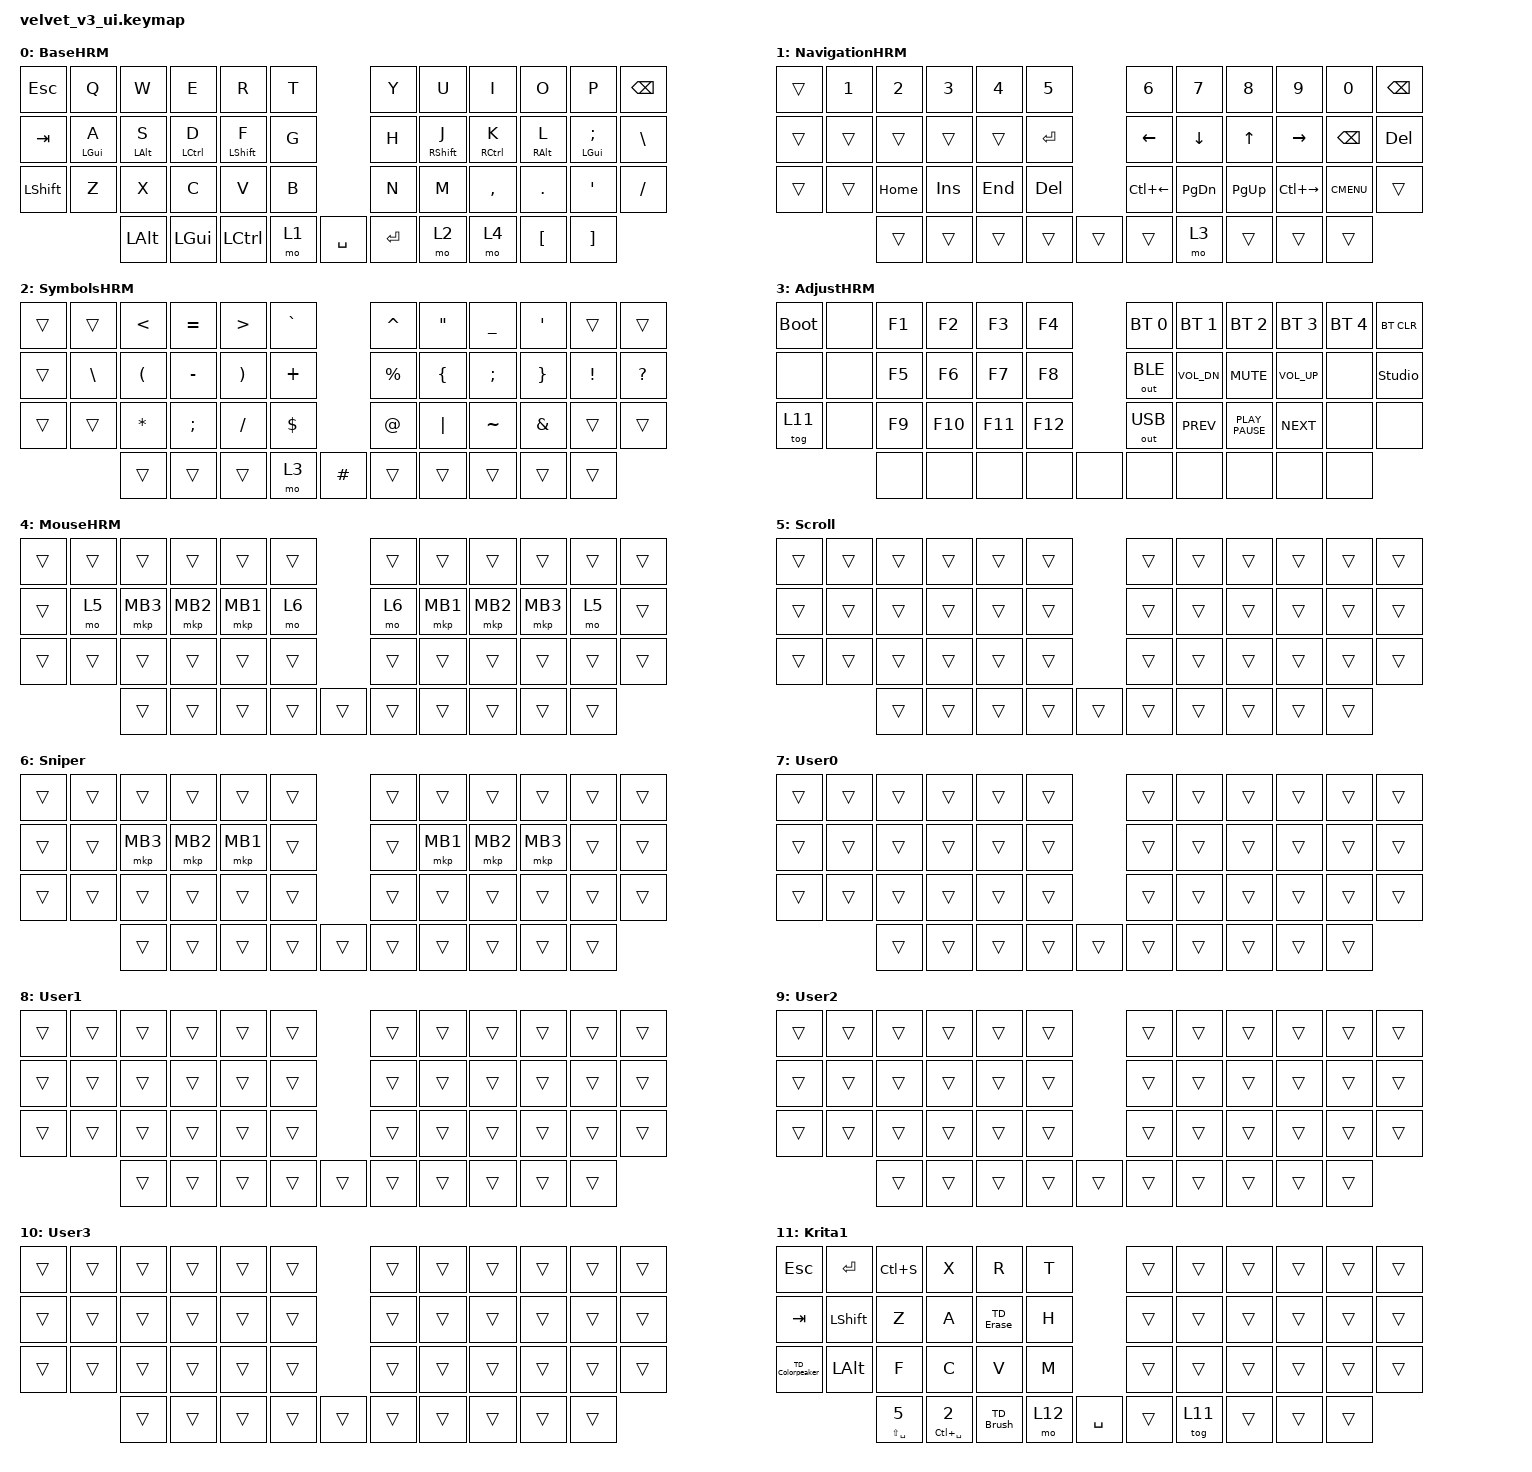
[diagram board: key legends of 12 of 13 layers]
#include <dt-bindings/zmk/input_transform.h>
#include <input/processors.dtsi>
#include <zephyr/dt-bindings/input/input-event-codes.h>
#include <behaviors.dtsi>
#include <dt-bindings/zmk/bt.h>
#include <dt-bindings/zmk/keys.h>
#include <dt-bindings/zmk/outputs.h>
#include <dt-bindings/zmk/pointing.h>

/ {
    behaviors {
        cap_sen: cap_sen {
            compatible = "zmk,behavior-hold-tap";
            label = "CAP_SEN";
            bindings = <&mo>, <&mkp>;

            #binding-cells = <2>;
            tapping-term-ms = <150>;
        };

        hrml: hrml {
            compatible = "zmk,behavior-hold-tap";
            label = "HRML";
            bindings = <&kp>, <&kp>;

            #binding-cells = <2>;
            tapping-term-ms = <200>;
            quick-tap-ms = <175>;
            require-prior-idle-ms = <150>;
            flavor = "balanced";
            hold-trigger-on-release;
            hold-trigger-key-positions = <6 7 8 9 10 11 18 19 20 21 22 23 30 31 32 33 34 35 42 43 44 45 41>;
        };

        hrmr: hrmr {
            compatible = "zmk,behavior-hold-tap";
            label = "HRMR";
            bindings = <&kp>, <&kp>;

            #binding-cells = <2>;
            tapping-term-ms = <200>;
            quick-tap-ms = <175>;
            require-prior-idle-ms = <150>;
            flavor = "balanced";
            hold-trigger-on-release;
            hold-trigger-key-positions = <0 1 2 3 4 5 12 13 14 15 16 17 24 25 26 27 28 29 36 37 38 39 40>;
        };

        TD_Brush: TD_Brush {
            compatible = "zmk,behavior-tap-dance";
            label = "TD_BRUSH";
            #binding-cells = <0>;
            bindings = <&kp B>, <&kp Q>;
        };

        TD_Erase: TD_Erase {
            compatible = "zmk,behavior-tap-dance";
            label = "TD_ERASE";
            #binding-cells = <0>;
            bindings = <&kp E>, <&kp LA(E)>;
        };

        TD_Colorpeaker: TD_Colorpeaker {
            compatible = "zmk,behavior-tap-dance";
            label = "TD_COLORPEAKER";
            #binding-cells = <0>;
            bindings = <&kp LCTRL>, <&kp LA(LCTRL)>;
        };
    };

    combos {
        compatible = "zmk,combos";

        tilde {
            bindings = <&kp GRAVE>;
            key-positions = <3 4>;
            layers = <0>;
        };
    };

    keymap {
        compatible = "zmk,keymap";

        BaseHRM {
            label = "BaseHRM";
            bindings = <
&kp ESC    &kp Q             &kp W             &kp E          &kp R               &kp T                        &kp Y  &kp U          &kp I          &kp O         &kp P                 &kp BSPC
&kp TAB    &hrml LEFT_GUI A  &hrml LEFT_ALT S  &hrml LCTRL D  &hrml LEFT_SHIFT F  &kp G                        &kp H  &hrmr RSHFT J  &hrmr RCTRL K  &hrmr RALT L  &hrmr LGUI SEMICOLON  &kp BSLH
&kp LSHFT  &kp Z             &kp X             &kp C          &kp V               &kp B                        &kp N  &kp M          &kp COMMA      &kp DOT       &kp SQT               &kp SLASH
                             &kp LALT          &kp LGUI       &kp LCTRL           &mo 1  &kp SPACE    &kp RET  &mo 2  &mo 4          &kp LBKT       &kp RBKT
            >;
        };

        NavigationHRM {
            label = "NavigationHRM";
            bindings = <
&trans  &kp N1  &kp N2    &kp N3   &kp N4   &kp N5                     &kp N6          &kp N7          &kp N8        &kp N9         &kp N0         &kp BACKSPACE
&trans  &trans  &trans    &trans   &trans   &kp RET                    &kp LEFT_ARROW  &kp DOWN_ARROW  &kp UP_ARROW  &kp RIGHT      &kp BACKSPACE  &kp DELETE
&trans  &trans  &kp HOME  &kp INS  &kp END  &kp DEL                    &kp LC(LEFT)    &kp PAGE_DOWN   &kp PAGE_UP   &kp LC(RIGHT)  &kp K_CMENU    &trans
                &trans    &trans   &trans   &trans   &trans    &trans  &mo 3           &trans          &trans        &trans
            >;
        };

        SymbolsHRM {
            label = "SymbolsHRM";
            bindings = <
&trans  &trans    &kp LT    &kp EQUAL  &kp GT    &kp GRAVE                      &kp CARET  &kp DQT   &kp UNDER  &kp SQT   &trans    &trans
&trans  &kp BSLH  &kp LPAR  &kp MINUS  &kp RPAR  &kp PLUS                       &kp PRCNT  &kp LBRC  &kp SEMI   &kp RBRC  &kp EXCL  &kp QUESTION
&trans  &trans    &kp STAR  &kp SEMI   &kp FSLH  &kp DLLR                       &kp AT     &kp PIPE  &kp TILDE  &kp AMPS  &trans    &trans
                  &trans    &trans     &trans    &mo 3      &kp HASH    &trans  &trans     &trans    &trans     &trans
            >;
        };

        AdjustHRM {
            label = "AdjustHRM";
            bindings = <
&bootloader  &none  &kp F1  &kp F2   &kp F3   &kp F4                   &bt BT_SEL 0  &bt BT_SEL 1  &bt BT_SEL 2      &bt BT_SEL 3  &bt BT_SEL 4  &bt BT_CLR
&none        &none  &kp F5  &kp F6   &kp F7   &kp F8                   &out OUT_BLE  &kp C_VOL_DN  &kp K_MUTE        &kp C_VOL_UP  &none         &studio_unlock
&tog 11      &none  &kp F9  &kp F10  &kp F11  &kp F12                  &out OUT_USB  &kp K_PREV    &kp K_PLAY_PAUSE  &kp K_NEXT    &none         &none
                    &none   &none    &none    &none    &none    &none  &none         &none         &none             &none
            >;
        };

        MouseHRM {
            bindings = <
&trans  &trans  &trans    &trans    &trans    &trans                    &trans  &trans    &trans    &trans    &trans  &trans
&trans  &mo 5   &mkp MB3  &mkp MB2  &mkp MB1  &mo 6                     &mo 6   &mkp MB1  &mkp MB2  &mkp MB3  &mo 5   &trans
&trans  &trans  &trans    &trans    &trans    &trans                    &trans  &trans    &trans    &trans    &trans  &trans
                &trans    &trans    &trans    &trans  &trans    &trans  &trans  &trans    &trans    &trans
            >;
        };

        Scroll {
            bindings = <
&trans  &trans  &trans  &trans  &trans  &trans                    &trans  &trans  &trans  &trans  &trans  &trans
&trans  &trans  &trans  &trans  &trans  &trans                    &trans  &trans  &trans  &trans  &trans  &trans
&trans  &trans  &trans  &trans  &trans  &trans                    &trans  &trans  &trans  &trans  &trans  &trans
                &trans  &trans  &trans  &trans  &trans    &trans  &trans  &trans  &trans  &trans
            >;
        };

        Sniper {
            bindings = <
&trans  &trans  &trans    &trans    &trans    &trans                    &trans  &trans    &trans    &trans    &trans  &trans
&trans  &trans  &mkp MB3  &mkp MB2  &mkp MB1  &trans                    &trans  &mkp MB1  &mkp MB2  &mkp MB3  &trans  &trans
&trans  &trans  &trans    &trans    &trans    &trans                    &trans  &trans    &trans    &trans    &trans  &trans
                &trans    &trans    &trans    &trans  &trans    &trans  &trans  &trans    &trans    &trans
            >;
        };

        User0 {
            bindings = <
&trans  &trans  &trans  &trans  &trans  &trans                    &trans  &trans  &trans  &trans  &trans  &trans
&trans  &trans  &trans  &trans  &trans  &trans                    &trans  &trans  &trans  &trans  &trans  &trans
&trans  &trans  &trans  &trans  &trans  &trans                    &trans  &trans  &trans  &trans  &trans  &trans
                &trans  &trans  &trans  &trans  &trans    &trans  &trans  &trans  &trans  &trans
            >;

            label = "User0";
        };

        User1 {
            bindings = <
&trans  &trans  &trans  &trans  &trans  &trans                    &trans  &trans  &trans  &trans  &trans  &trans
&trans  &trans  &trans  &trans  &trans  &trans                    &trans  &trans  &trans  &trans  &trans  &trans
&trans  &trans  &trans  &trans  &trans  &trans                    &trans  &trans  &trans  &trans  &trans  &trans
                &trans  &trans  &trans  &trans  &trans    &trans  &trans  &trans  &trans  &trans
            >;

            label = "User1";
        };

        User2 {
            bindings = <
&trans  &trans  &trans  &trans  &trans  &trans                    &trans  &trans  &trans  &trans  &trans  &trans
&trans  &trans  &trans  &trans  &trans  &trans                    &trans  &trans  &trans  &trans  &trans  &trans
&trans  &trans  &trans  &trans  &trans  &trans                    &trans  &trans  &trans  &trans  &trans  &trans
                &trans  &trans  &trans  &trans  &trans    &trans  &trans  &trans  &trans  &trans
            >;

            label = "User2";
        };

        User3 {
            bindings = <
&trans  &trans  &trans  &trans  &trans  &trans                    &trans  &trans  &trans  &trans  &trans  &trans
&trans  &trans  &trans  &trans  &trans  &trans                    &trans  &trans  &trans  &trans  &trans  &trans
&trans  &trans  &trans  &trans  &trans  &trans                    &trans  &trans  &trans  &trans  &trans  &trans
                &trans  &trans  &trans  &trans  &trans    &trans  &trans  &trans  &trans  &trans
            >;

            label = "User3";
        };

        Krita1 {
            bindings = <
&kp ESC          &kp RET    &kp LC(S)         &kp X                   &kp R      &kp T                        &trans   &trans  &trans  &trans  &trans  &trans
&kp TAB          &kp LSHFT  &kp Z             &kp A                   &TD_Erase  &kp H                        &trans   &trans  &trans  &trans  &trans  &trans
&TD_Colorpeaker  &kp LALT   &kp F             &kp C                   &kp V      &kp M                        &trans   &trans  &trans  &trans  &trans  &trans
                            &mt LS(SPACE) N5  &mt LC(SPACE) NUMBER_2  &TD_Brush  &mo 12  &kp SPACE    &trans  &tog 11  &trans  &trans  &trans
            >;
        };

        Krita2 {
            bindings = <
&trans         &kp LC(G)           &kp LC(E)   &kp LC(T)      &kp INS    &kp LC(INS)                    &trans  &trans  &trans  &trans  &trans  &trans
&kp LC(LS(I))  &kp LS(LC(A))       &kp LC(A)   &kp LC(PG_UP)  &kp LA(H)  &kp LA(INS)                    &trans  &trans  &trans  &trans  &trans  &trans
&trans         &kp LC(LS(DELETE))  &kp DELETE  &kp LC(PG_DN)  &kp LS(H)  &kp LC(N)                      &trans  &trans  &trans  &trans  &trans  &trans
                                   &kp LC(C)   &kp LC(V)      &trans     &trans       &trans    &trans  &trans  &trans  &trans  &trans
            >;
        };
    };
};

&trackball_listener {
    input-processors = <&zip_xy_scaler 9 20>;

    scroller {
        layers = <5>;
        input-processors =
            <&zip_xy_transform (INPUT_TRANSFORM_Y_INVERT | INPUT_TRANSFORM_X_INVERT )>,
            <&zip_xy_scaler 1 32>,
            <&zip_xy_to_scroll_mapper>;
    };

    sniper {
        layers = <6>;
        input-processors = <&zip_xy_scaler 1 4>;
    };
};
